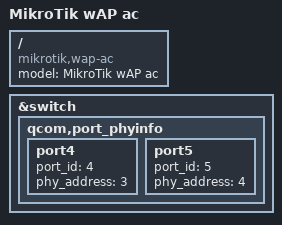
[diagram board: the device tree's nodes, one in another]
// SPDX-License-Identifier: GPL-2.0-or-later OR MIT
/* Copyright (c) 2020, Robert Marko <robimarko@gmail.com> */

#include "qcom-ipq4018-wap-ac.dtsi"

/ {
	model = "MikroTik wAP ac";
	compatible = "mikrotik,wap-ac";
};

/* QSDK 10: retain this board's physical LAN/WAN port assignment. */
#define QSDK_LAN_BMP 0x30
#define QSDK_WAN_BMP 0x0
#define QSDK_WAN_PHY 0
#define QSDK_WAN_POLL 0
#include "qcom-ipq40xx-qsdk-10.dtsi"

&switch {
	qcom,port_phyinfo {
		port4 { port_id = <4>; phy_address = <3>; };
		port5 { port_id = <5>; phy_address = <4>; };
	};
};
